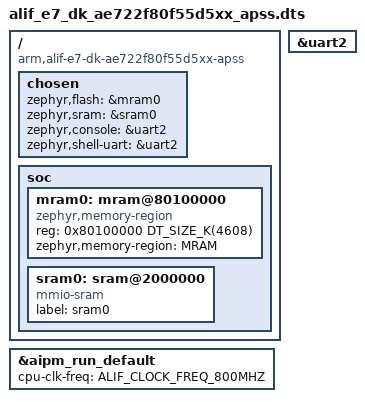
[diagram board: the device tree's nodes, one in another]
/* Copyright (c) 2025 Alif Semiconductor
 *
 * SPDX-License-Identifier: Apache-2.0
 */

/dts-v1/;

#include <mem.h>
#include <zephyr/dt-bindings/interrupt-controller/arm-gic.h>
#include <zephyr/dt-bindings/pinctrl/ensemble-pinctrl.h>
#include <zephyr/dt-bindings/clock/alif_ensemble_clocks.h>
#include "arm/alif/ensemble/common/ensemble_apss.dtsi"
#include <alif/ensemble/e7/ae722f80f55d5xx_apss.dtsi>
#include "../common/ensemble-pinctrl.dtsi"

&uart2 {
	status = "okay";
};

&aipm_run_default {
	cpu-clk-freq = <ALIF_CLOCK_FREQ_800MHZ>;
};

/ {
	compatible = "arm,alif-e7-dk-ae722f80f55d5xx-apss";
	#address-cells = <1>;
	#size-cells = <1>;

	chosen {
		zephyr,flash = &mram0;
		zephyr,sram = &sram0;
		zephyr,console = &uart2;
		zephyr,shell-uart = &uart2;
	};

	soc {
		mram0: mram@80100000 {
			compatible = "zephyr,memory-region";
			reg = <0x80100000 DT_SIZE_K(4608)>;
			zephyr,memory-region = "MRAM";
		};

		// The base sram0 node also select "zephyr,memory-region" compatible
		// which add some node property that we are not used in our case
		sram0: sram@2000000 {
			compatible = "mmio-sram";
			label = "sram0";
			status = "okay";
			/delete-property/ zephyr,memory-region;
			/delete-property/ zephyr,memory-attr;
		};
	};
};
